VERSION ""

NS_ :

BS_:

BU_: IMU

BO_ 814 Latitude: 8 Vector__XXX
 SG_ PosLat2 : 0|64@1- (1E-008,0) [-90|90] "deg" Vector__XXX

BO_ 813 Longitude: 8 Vector__XXX
 SG_ PosLon2 : 0|64@1- (1E-008,0) [-180|180] "deg" Vector__XXX

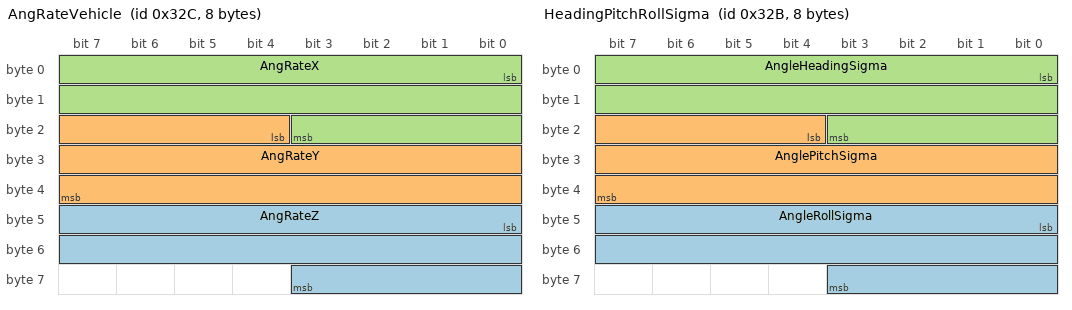
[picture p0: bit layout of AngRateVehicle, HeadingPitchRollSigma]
BO_ 812 AngRateVehicle: 8 IMU
 SG_ AngRateZ : 40|20@1- (0.01,0) [-500|500] "deg/s" Vector__XXX
 SG_ AngRateY : 20|20@1- (0.01,0) [-500|500] "deg/s" Vector__XXX
 SG_ AngRateX : 0|20@1- (0.01,0) [-500|500] "deg/s" Vector__XXX

BO_ 811 HeadingPitchRollSigma: 8 IMU
 SG_ AngleRollSigma : 40|20@1+ (0.0001,0) [0|100] "deg" Vector__XXX
 SG_ AnglePitchSigma : 20|20@1+ (0.0001,0) [0|100] "deg" Vector__XXX
 SG_ AngleHeadingSigma : 0|20@1+ (0.0001,0) [0|100] "deg" Vector__XXX

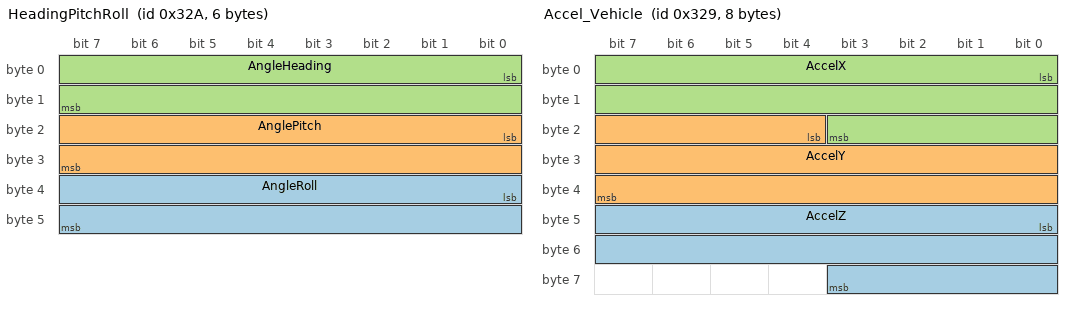
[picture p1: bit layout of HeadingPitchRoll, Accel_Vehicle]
BO_ 810 HeadingPitchRoll: 6 IMU
 SG_ AngleRoll : 32|16@1- (0.01,0) [-180|180] "deg" Vector__XXX
 SG_ AnglePitch : 16|16@1- (0.01,0) [-90|90] "deg" Vector__XXX
 SG_ AngleHeading : 0|16@1+ (0.01,0) [0|360] "deg" Vector__XXX

BO_ 809 Accel_Vehicle: 8 IMU
 SG_ AccelZ : 40|20@1- (0.0001,0) [-8|8] "g" Vector__XXX
 SG_ AccelY : 20|20@1- (0.0001,0) [-8|8] "g" Vector__XXX
 SG_ AccelX : 0|20@1- (0.0001,0) [-8|8] "g" Vector__XXX

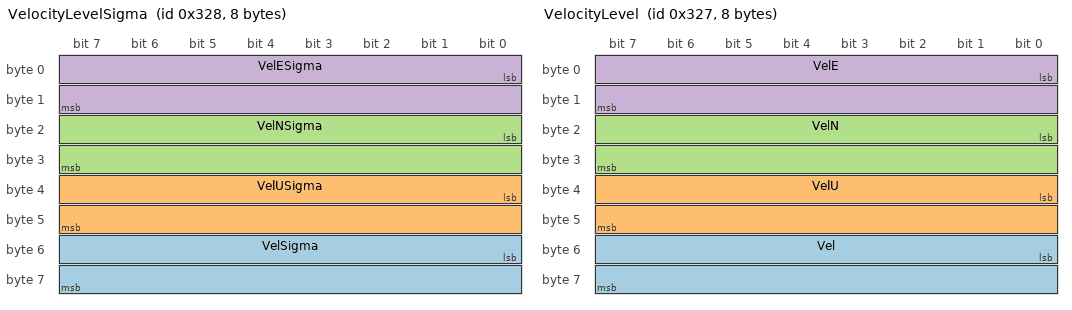
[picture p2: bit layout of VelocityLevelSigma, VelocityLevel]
BO_ 808 VelocityLevelSigma: 8 IMU
 SG_ VelSigma : 48|16@1+ (0.001,0) [0|65.535] "m/s" Vector__XXX
 SG_ VelUSigma : 32|16@1+ (0.001,0) [0|65.535] "m/s" Vector__XXX
 SG_ VelNSigma : 16|16@1+ (0.001,0) [0|65.535] "m/s" Vector__XXX
 SG_ VelESigma : 0|16@1+ (0.001,0) [0|65.535] "m/s" Vector__XXX

BO_ 800 Time: 6 IMU
 SG_ GpsTime : 16|32@1+ (0.001,0) [0|4294967.295] "s" Vector__XXX
 SG_ GpsWeek : 0|16@1+ (1,0) [0|65535] "w" Vector__XXX

BO_ 807 VelocityLevel: 8 IMU
 SG_ Vel : 48|16@1- (0.01,0) [-327.68|327.67] "m/s" Vector__XXX
 SG_ VelU : 32|16@1- (0.01,0) [-327.68|327.67] "m/s" Vector__XXX
 SG_ VelN : 16|16@1- (0.01,0) [-327.68|327.67] "m/s" Vector__XXX
 SG_ VelE : 0|16@1- (0.01,0) [-327.68|327.67] "m/s" Vector__XXX

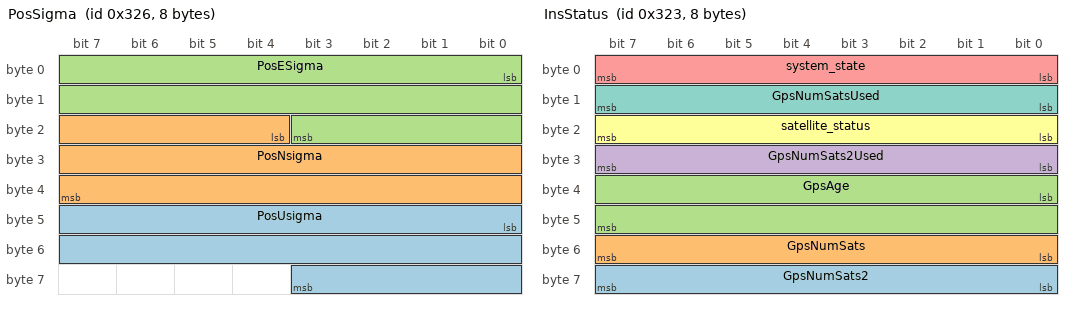
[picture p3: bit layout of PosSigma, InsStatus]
BO_ 806 PosSigma: 8 IMU
 SG_ PosUsigma : 40|20@1+ (0.0001,0) [0|100] "m" Vector__XXX
 SG_ PosNsigma : 20|20@1+ (0.0001,0) [0|100] "m" Vector__XXX
 SG_ PosESigma : 0|20@1+ (0.0001,0) [0|100] "m" Vector__XXX

BO_ 805 Altitude: 4 IMU
 SG_ PosAlt : 0|32@1- (0.001,0) [-2147483.648|2147483.648] "m" Vector__XXX

BO_ 804 LatitudeLongitude: 8 IMU
 SG_ PosLon : 32|32@1- (1E-007,0) [-214.7483648|214.7483648] "deg" Vector__XXX
 SG_ PosLat : 0|32@1- (1E-007,0) [-214.7483648|214.7483648] "deg" Vector__XXX

BO_ 803 InsStatus: 8 IMU
 SG_ GpsNumSats2 : 56|8@1+ (1,0) [0|255] "" Vector__XXX
 SG_ GpsNumSats : 48|8@1+ (1,0) [0|255] "" Vector__XXX
 SG_ GpsAge : 32|16@1+ (0.01,0) [0|655.35] "" Vector__XXX
 SG_ GpsNumSats2Used : 24|8@1+ (1,0) [0|255] "" Vector__XXX
 SG_ system_state : 0|8@1+ (1,0) [0|9] "" Vector__XXX
 SG_ satellite_status : 16|8@1+ (1,0) [0|9] "" Vector__XXX
 SG_ GpsNumSatsUsed : 8|8@1+ (1,0) [0|255] "" Vector__XXX

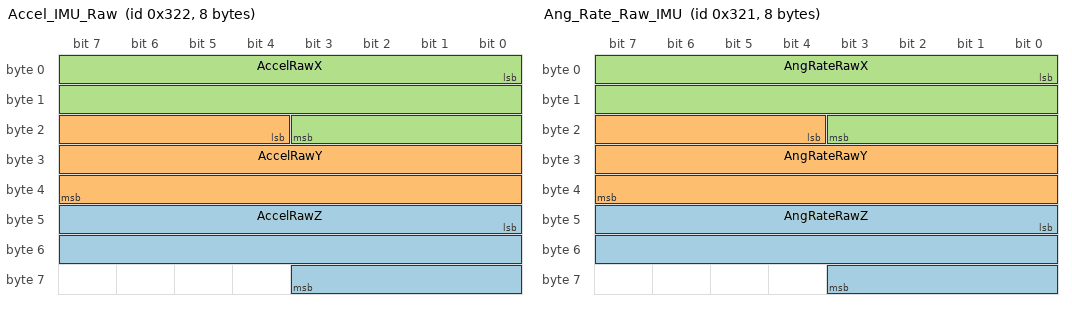
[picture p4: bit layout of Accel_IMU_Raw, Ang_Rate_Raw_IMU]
BO_ 802 Accel_IMU_Raw: 8 IMU
 SG_ AccelRawZ : 40|20@1- (0.0001,0) [-50|50] "g" Vector__XXX
 SG_ AccelRawY : 20|20@1- (0.0001,0) [-50|50] "g" Vector__XXX
 SG_ AccelRawX : 0|20@1- (0.0001,0) [-50|50] "g" Vector__XXX

BO_ 801 Ang_Rate_Raw_IMU: 8 IMU
 SG_ AngRateRawZ : 40|20@1- (0.01,0) [-500|500] "deg/s" Vector__XXX
 SG_ AngRateRawY : 20|20@1- (0.01,0) [-500|500] "deg/s" Vector__XXX
 SG_ AngRateRawX : 0|20@1- (0.01,0) [-500|500] "deg/s" Vector__XXX

BA_DEF_ SG_  "GenSigSendType" ENUM  "Cyclic","OnWrite","OnWriteWithRepetition","OnChange","OnChangeWithRepetition","IfActive","IfActiveWithRepetition","NoSigSendType";
BA_DEF_ BO_  "GenMsgSendType" ENUM  "Cyclic","not_used","not_used","not_used","not_used","Cyclic","not_used","IfActive","NoMsgSendType";
BA_DEF_  "DBName" STRING ;
BA_DEF_  "BusType" STRING ;
BA_DEF_DEF_  "GenSigSendType" "Cyclic";
BA_DEF_DEF_  "GenMsgSendType" "NoMsgSendType";
BA_DEF_DEF_  "DBName" "";
BA_DEF_DEF_  "BusType" "CAN";
BA_ "DBName" "CANProtocol";
